# R7FA4W1AD register map
Vendor: Renesas; Series: RA4; File version: 1.0
CPU: CM4 r0p1, little endian, MPU, FPU, VTOR, 4 interrupt priority bits
Registers are 8-bit, read-write, reset 0x0 unless marked. A register's access mark holds for its fields unless they carry their own. Offsets are from the block's base; [hi:lo] are bit positions; {n}, {i} and the like mark numbered series; 'fields as' and 'values as' point back to an identical list.

## SRAM — SRAM Control
Base 0x40002000
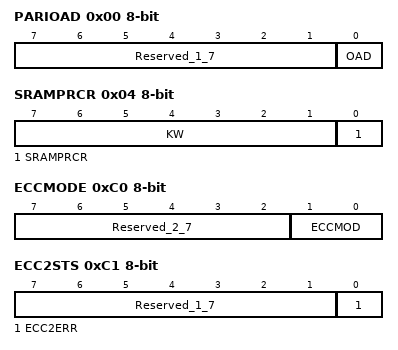
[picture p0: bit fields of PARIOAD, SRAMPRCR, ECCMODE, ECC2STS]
0x00 PARIOAD — SRAM Parity Error Operation After Detection Register
  [7:1] Reserved_1_7 — These bits are read as 0000000. The write value should be 0000000.
  [0] OAD — Operation after Detection
0x04 SRAMPRCR — SRAM Protection Register
  [7:1] KW wo — Write Key Code
  [0] SRAMPRCR — Register Write Control
0xC0 ECCMODE — ECC Operating Mode Control Register
  [7:2] Reserved_2_7 — These bits are read as 000000. The write value should be 000000.
  [1:0] ECCMOD — ECC Operating Mode Select
0xC1 ECC2STS — ECC 2-Bit Error Status Register
  [7:1] Reserved_1_7 — These bits are read as 0000000. The write value should be 0000000.
  [0] ECC2ERR write-0-clears read-modifies — ECC 2-Bit Error Status
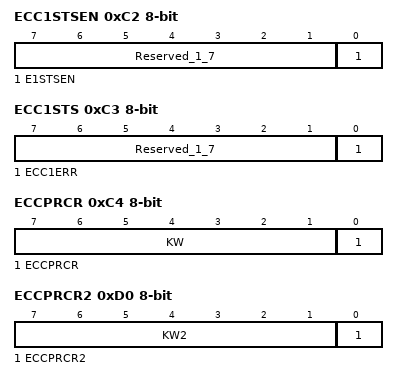
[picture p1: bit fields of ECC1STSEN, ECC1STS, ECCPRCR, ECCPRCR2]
0xC2 ECC1STSEN — ECC 1-Bit Error Information Update Enable Register
  [7:1] Reserved_1_7 — These bits are read as 0000000. The write value should be 0000000.
  [0] E1STSEN — ECC 1-Bit Error Information Update Enable
0xC3 ECC1STS — ECC 1-Bit Error Status Register
  [7:1] Reserved_1_7 — These bits are read as 0000000. The write value should be 0000000.
  [0] ECC1ERR write-0-clears read-modifies — ECC 1-Bit Error Status
0xC4 ECCPRCR — ECC Protection Register
  [7:1] KW wo — Write Key Code
  [0] ECCPRCR — Register Write Control
0xD0 ECCPRCR2 — ECC Protection Register 2
  [7:1] KW2 wo — Write Key Code
  [0] ECCPRCR2 — Register Write Control
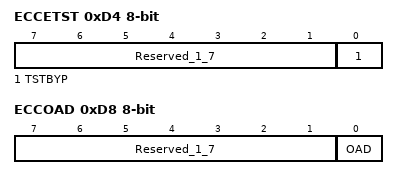
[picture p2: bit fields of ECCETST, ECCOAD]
0xD4 ECCETST — ECC Test Control Register
  [7:1] Reserved_1_7 — These bits are read as 0000000. The write value should be 0000000.
  [0] TSTBYP — ECC Bypass Select
0xD8 ECCOAD — SRAM ECC Error Operation After Detection Register
  fields as PARIOAD

## MMPU — Bus Master MPU
Base 0x40000000
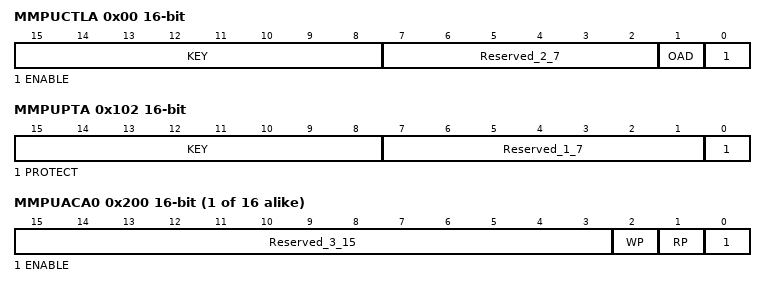
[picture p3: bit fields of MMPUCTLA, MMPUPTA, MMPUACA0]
0x00 MMPUCTLA 16-bit — Bus Master MPU Control Register A
  [15:8] KEY wo — Key CodeThese bits are used to enable or disable writing of the OAD and ENABLE bit.
  [7:2] Reserved_2_7 — These bits are read as 000000. The write value should be 000000.
  [1] OAD — Operation after detection
  [0] ENABLE — Master Group enable
0x102 MMPUPTA 16-bit — Group A Protection of Register
  [15:8] KEY wo — Write Keyword The data written to these bits are not stored.
  [7:1] Reserved_1_7 — These bits are read as 0000000. The write value should be 0000000.
  [0] PROTECT — Protection of register(MMPUSAn, MMPUEAn and MMPUACAn)
{0x200+0x10*i} MMPUACA{i} (i=0..15) 16-bit — Group A Region {i} Access Control Register
  [15:3] Reserved_3_15 — These bits are read as 0000000000000. The write value should be 0000000000000.
  [2] WP — Write protection
  [1] RP — Read protection
  [0] ENABLE — Region enable
{0x204+0x10*i} MMPUSA{i} (i=0..15) 32-bit (reset mask 0x3) — Group A Region {i} Start Address Register
  [31:0] MMPUSA — Address where the region starts, for use in region determination.NOTE: The low,order 2 bits are fixed to 0.
{0x208+0x10*i} MMPUEA{i} (i=0..15) 32-bit reset 0x3 (reset mask 0x3) — Group A Region {i} End Address Register
  [31:0] MMPUEA — Region end address registerAddress where the region end, for use in region determination.NOTE: The low,order 2 bits are fixed to 1.

## SMPU — Bus Slave MPU
Base 0x40000C00
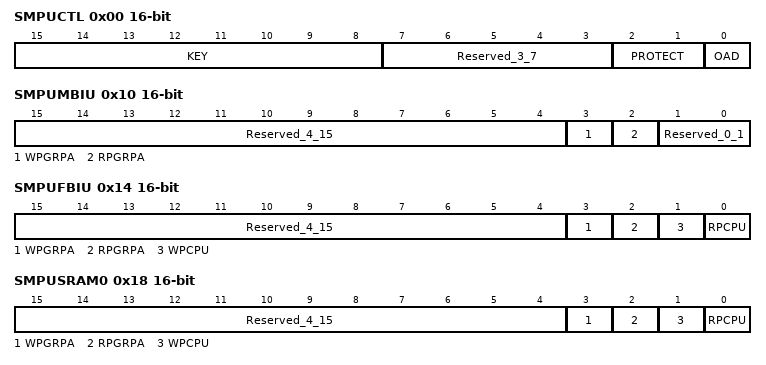
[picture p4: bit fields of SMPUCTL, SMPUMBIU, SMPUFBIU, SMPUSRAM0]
0x00 SMPUCTL 16-bit — Slave MPU Control Register
  [15:8] KEY — Key Code This bit is used to enable or disable rewriting of the PROTECT and OAD bit.
  [7:3] Reserved_3_7 — These bits are read as 00000. The write value should be 00000.
  [2:1] PROTECT — Protection of register Protected register SMPUMBIU, SMPUFBIU, SMPUSRAM0, SMPUP0BIU, SMPUP2BIU, SMPUP6BIU,SMPUEXBIU, SMPUEXBIU2
  [0] OAD — Master Group enable
0x10 SMPUMBIU 16-bit — Access Control Register for MBIU
  [15:4] Reserved_4_15 — These bits are read as 000000000000. The write value should be 000000000000.
  [3] WPGRPA — Master Group A Write protection
  [2] RPGRPA — Master Group A Read protection
  [1:0] Reserved_0_1 — These bits are read as 00. The write value should be 00.
0x14 SMPUFBIU 16-bit — Access Control Register for FBIU
  [15:4] Reserved_4_15 — These bits are read as 000000000000. The write value should be 000000000000.
  [3] WPGRPA — Master Group A Write protection
  [2] RPGRPA — Master Group A Read protection
  [1] WPCPU — CPU Write protection
  [0] RPCPU — CPU Read protection
0x18 SMPUSRAM0 16-bit — Access Control Register for SRAM0
  fields as SMPUFBIU
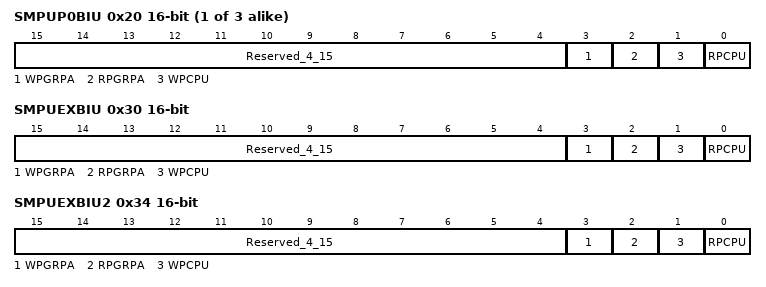
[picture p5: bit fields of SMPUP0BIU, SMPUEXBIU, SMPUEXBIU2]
0x20 SMPUP{x}BIU (x=0,2,6; step 0x4) 16-bit — Access Control Register for P{x}BIU
  fields as SMPUFBIU
0x30 SMPUEXBIU 16-bit — Access Control Register for EXBIU
  fields as SMPUFBIU
0x34 SMPUEXBIU2 16-bit — Access Control Register for EXBIU2
  fields as SMPUFBIU
